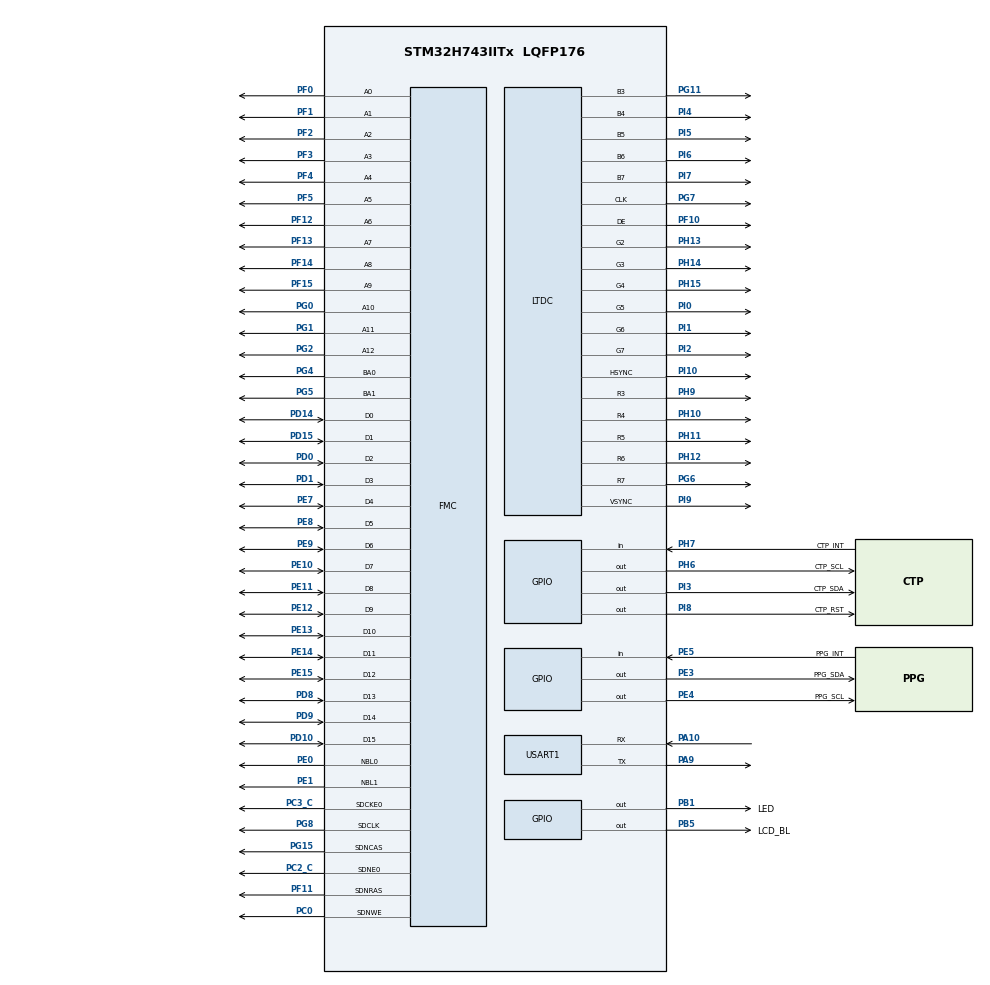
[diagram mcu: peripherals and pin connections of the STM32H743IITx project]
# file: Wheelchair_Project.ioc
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CORTEX_M7.AccessPermission_S-Cortex_Memory_Protection_Unit_Region1_Settings_S=MPU_REGION_FULL_ACCESS
CORTEX_M7.AccessPermission_S-Cortex_Memory_Protection_Unit_Region2_Settings_S=MPU_REGION_FULL_ACCESS
CORTEX_M7.AccessPermission_S-Cortex_Memory_Protection_Unit_Region3_Settings_S=MPU_REGION_FULL_ACCESS
CORTEX_M7.AccessPermission_S-Cortex_Memory_Protection_Unit_Region4_Settings_S=MPU_REGION_FULL_ACCESS
CORTEX_M7.AccessPermission_S-Cortex_Memory_Protection_Unit_Region5_Settings_S=MPU_REGION_FULL_ACCESS
CORTEX_M7.AccessPermission_S-Cortex_Memory_Protection_Unit_Region6_Settings_S=MPU_REGION_FULL_ACCESS
CORTEX_M7.AccessPermission_Spec=MPU_REGION_FULL_ACCESS
CORTEX_M7.BaseAddress_S-Cortex_Memory_Protection_Unit_Region1_Settings_S=0x24000000
CORTEX_M7.BaseAddress_S-Cortex_Memory_Protection_Unit_Region2_Settings_S=0x30000000
CORTEX_M7.BaseAddress_S-Cortex_Memory_Protection_Unit_Region3_Settings_S=0x38000000
CORTEX_M7.BaseAddress_S-Cortex_Memory_Protection_Unit_Region4_Settings_S=0x60000000
CORTEX_M7.BaseAddress_S-Cortex_Memory_Protection_Unit_Region5_Settings_S=0xC0000000
CORTEX_M7.BaseAddress_S-Cortex_Memory_Protection_Unit_Region6_Settings_S=0x80000000
CORTEX_M7.BaseAddress_Spec=0x20000000
CORTEX_M7.CPU_DCache=Enabled
CORTEX_M7.CPU_ICache=Enabled
CORTEX_M7.DisableExec_S-Cortex_Memory_Protection_Unit_Region6_Settings_S=MPU_INSTRUCTION_ACCESS_DISABLE
CORTEX_M7.DisableExec_Spec=MPU_INSTRUCTION_ACCESS_ENABLE
CORTEX_M7.Enable_S-Cortex_Memory_Protection_Unit_Region1_Settings_S=MPU_REGION_ENABLE
CORTEX_M7.Enable_S-Cortex_Memory_Protection_Unit_Region2_Settings_S=MPU_REGION_ENABLE
CORTEX_M7.Enable_S-Cortex_Memory_Protection_Unit_Region3_Settings_S=MPU_REGION_ENABLE
CORTEX_M7.Enable_S-Cortex_Memory_Protection_Unit_Region4_Settings_S=MPU_REGION_ENABLE
CORTEX_M7.Enable_S-Cortex_Memory_Protection_Unit_Region5_Settings_S=MPU_REGION_ENABLE
CORTEX_M7.Enable_S-Cortex_Memory_Protection_Unit_Region6_Settings_S=MPU_REGION_ENABLE
CORTEX_M7.IsBufferable_S-Cortex_Memory_Protection_Unit_Region2_Settings_S=MPU_ACCESS_BUFFERABLE
CORTEX_M7.IsBufferable_S-Cortex_Memory_Protection_Unit_Region3_Settings_S=MPU_ACCESS_BUFFERABLE
CORTEX_M7.IsBufferable_S-Cortex_Memory_Protection_Unit_Region5_Settings_S=MPU_ACCESS_BUFFERABLE
CORTEX_M7.IsBufferable_Spec=MPU_ACCESS_BUFFERABLE
CORTEX_M7.IsCacheable_S-Cortex_Memory_Protection_Unit_Region1_Settings_S=MPU_ACCESS_CACHEABLE
CORTEX_M7.IsCacheable_S-Cortex_Memory_Protection_Unit_Region2_Settings_S=MPU_ACCESS_CACHEABLE
CORTEX_M7.IsCacheable_S-Cortex_Memory_Protection_Unit_Region3_Settings_S=MPU_ACCESS_CACHEABLE
CORTEX_M7.IsCacheable_S-Cortex_Memory_Protection_Unit_Region5_Settings_S=MPU_ACCESS_CACHEABLE
CORTEX_M7.IsCacheable_Spec=MPU_ACCESS_CACHEABLE
CORTEX_M7.IsShareable_S-Cortex_Memory_Protection_Unit_Region1_Settings_S=MPU_ACCESS_SHAREABLE
CORTEX_M7.IsShareable_Spec=MPU_ACCESS_NOT_SHAREABLE
CORTEX_M7.Size_S-Cortex_Memory_Protection_Unit_Region1_Settings_S=MPU_REGION_SIZE_512KB
CORTEX_M7.Size_S-Cortex_Memory_Protection_Unit_Region2_Settings_S=MPU_REGION_SIZE_512KB
CORTEX_M7.Size_S-Cortex_Memory_Protection_Unit_Region3_Settings_S=MPU_REGION_SIZE_64KB
CORTEX_M7.Size_S-Cortex_Memory_Protection_Unit_Region4_Settings_S=MPU_REGION_SIZE_64MB
CORTEX_M7.Size_S-Cortex_Memory_Protection_Unit_Region5_Settings_S=MPU_REGION_SIZE_32MB
CORTEX_M7.Size_S-Cortex_Memory_Protection_Unit_Region6_Settings_S=MPU_REGION_SIZE_256MB
CORTEX_M7.Size_Spec=MPU_REGION_SIZE_128KB
CORTEX_M7.SubRegionDisable_Spec=0x0
CORTEX_M7.default_mode_Activation=1
DMA2D.ColorMode=DMA2D_OUTPUT_RGB888
FMC.CASLatency1=FMC_SDRAM_CAS_LATENCY_3
FMC.ColumnBitsNumber1=FMC_SDRAM_COLUMN_BITS_NUM_9
FMC.ExitSelfRefreshDelay1=8
FMC.LoadToActiveDelay1=2
FMC.RCDDelay1=2
FMC.RPDelay1=2
FMC.RPDelay2=2
FMC.ReadBurst1=FMC_SDRAM_RBURST_ENABLE
FMC.ReadBurst2=FMC_SDRAM_RBURST_ENABLE
FMC.ReadPipeDelay1=FMC_SDRAM_RPIPE_DELAY_1
FMC.ReadPipeDelay2=FMC_SDRAM_RPIPE_DELAY_1
FMC.RowCycleDelay1=6
FMC.RowCycleDelay2=6
FMC.SDClockPeriod1=FMC_SDRAM_CLOCK_PERIOD_2
FMC.SDClockPeriod2=FMC_SDRAM_CLOCK_PERIOD_2
FMC.SelfRefreshTime1=6
FMC.WriteRecoveryTime1=4
FREERTOS.Queues01=Queue_PPG_IR,16,float64_t,0,Dynamic,NULL,NULL;Queue_PPG_Red,16,float64_t,0,Dynamic,NULL,NULL
FREERTOS.Tasks01=touchGFX,0,2048,TouchGFX_Task,As weak,NULL,Dynamic,NULL,NULL;taskPPG,-1,1024,PPG_Task,Default,NULL,Dynamic,NULL,NULL;filterTask,1,1024,FilterTask,Default,NULL,Dynamic,NULL,NULL
FREERTOS.configENABLE_FPU=1
FREERTOS.configTOTAL_HEAP_SIZE=32768
FREERTOS.configUSE_APPLICATION_TASK_TAG=1
LTDC.ActiveW=800
LTDC.Alpha_L0=255
LTDC.Blue_L0=255
LTDC.FBStartAdress_L0=0xC0000000
LTDC.HBP=8
LTDC.HFP=8
LTDC.HSync=4
LTDC.ImageHeight_L0=480
LTDC.ImageWidth_L0=800
LTDC.Layers=0
LTDC.PixelFormat_L0=LTDC_PIXEL_FORMAT_RGB565
LTDC.Red=0xFF
LTDC.VBP=16
LTDC.VFP=20
LTDC.WindowX1_L0=800
LTDC.WindowY1_L0=480
Mcu.Family=STM32H7
Mcu.Name=STM32H743IITx
Mcu.Package=LQFP176
NVIC.DMA2D_IRQn=true\:9\:0\:true\:false\:true\:true\:true\:true\:true
NVIC.LTDC_IRQn=true\:9\:0\:true\:false\:true\:true\:true\:true\:true
NVIC.PriorityGroup=NVIC_PRIORITYGROUP_4
NVIC.TIM6_DAC_IRQn=true\:0\:0\:true\:false\:true\:false\:false\:true\:true
NVIC.TimeBase=TIM6_DAC_IRQn
NVIC.TimeBaseIP=TIM6
PA10.Mode=Asynchronous
PA10.Signal=USART1_RX
PA13\ (JTMS/SWDIO).Mode=Serial_Wire
PA13\ (JTMS/SWDIO).Signal=DEBUG_JTMS-SWDIO
PA14\ (JTCK/SWCLK).Mode=Serial_Wire
PA14\ (JTCK/SWCLK).Signal=DEBUG_JTCK-SWCLK
PA9.Mode=Asynchronous
PA9.Signal=USART1_TX
PB1.GPIO_Label=LED
PB1.GPIO_PuPd=GPIO_PULLDOWN
PB1.Signal=GPIO_Output
PB5.GPIO_Label=LCD_BL
PB5.GPIO_PuPd=GPIO_PULLUP
PB5.PinState=GPIO_PIN_SET
PB5.Signal=GPIO_Output
PC0.Signal=FMC_SDNWE
PC14-OSC32_IN\ (OSC32_IN).Mode=LSE-External-Oscillator
PC14-OSC32_IN\ (OSC32_IN).Signal=RCC_OSC32_IN
PC15-OSC32_OUT\ (OSC32_OUT).Mode=LSE-External-Oscillator
PC15-OSC32_OUT\ (OSC32_OUT).Signal=RCC_OSC32_OUT
PC2_C.Mode=SdramChipSelect1_1
PC2_C.Signal=FMC_SDNE0
PC3_C.Mode=SdramChipSelect1_1
PC3_C.Signal=FMC_SDCKE0
PD0.Signal=FMC_D2_DA2
PD1.Signal=FMC_D3_DA3
PD10.Signal=FMC_D15_DA15
PD14.Signal=FMC_D0_DA0
PD15.Signal=FMC_D1_DA1
PD8.Signal=FMC_D13_DA13
PD9.Signal=FMC_D14_DA14
PE0.Signal=FMC_NBL0
PE1.Signal=FMC_NBL1
PE10.Signal=FMC_D7_DA7
PE11.Signal=FMC_D8_DA8
PE12.Signal=FMC_D9_DA9
PE13.Signal=FMC_D10_DA10
PE14.Signal=FMC_D11_DA11
PE15.Signal=FMC_D12_DA12
PE3.GPIO_Label=PPG_SDA
PE3.GPIO_ModeDefaultOutputPP=GPIO_MODE_OUTPUT_OD
PE3.GPIO_PuPd=GPIO_NOPULL
PE3.GPIO_Speed=GPIO_SPEED_FREQ_VERY_HIGH
PE3.Signal=GPIO_Output
PE4.GPIO_Label=PPG_SCL
PE4.GPIO_ModeDefaultOutputPP=GPIO_MODE_OUTPUT_OD
PE4.GPIO_PuPd=GPIO_NOPULL
PE4.GPIO_Speed=GPIO_SPEED_FREQ_VERY_HIGH
PE4.Signal=GPIO_Output
PE5.GPIO_Label=PPG_INT
PE5.GPIO_PuPd=GPIO_PULLUP
PE5.Signal=GPIO_Input
PE7.Signal=FMC_D4_DA4
PE8.Signal=FMC_D5_DA5
PE9.Signal=FMC_D6_DA6
PF0.Signal=FMC_A0
PF1.Signal=FMC_A1
PF10.GPIO_Speed=GPIO_SPEED_FREQ_VERY_HIGH
PF10.Mode=RGB565
PF10.Signal=LTDC_DE
PF11.Signal=FMC_SDNRAS
PF12.Signal=FMC_A6
PF13.Signal=FMC_A7
PF14.Signal=FMC_A8
PF15.Signal=FMC_A9
PF2.Signal=FMC_A2
PF3.Signal=FMC_A3
PF4.Signal=FMC_A4
PF5.Signal=FMC_A5
PG0.Signal=FMC_A10
PG1.Signal=FMC_A11
PG11.GPIO_Speed=GPIO_SPEED_FREQ_VERY_HIGH
PG11.Mode=RGB565
PG11.Signal=LTDC_B3
PG15.Signal=FMC_SDNCAS
PG2.Signal=FMC_A12
PG4.Signal=FMC_A14_BA0
PG5.Signal=FMC_A15_BA1
PG6.GPIO_Speed=GPIO_SPEED_FREQ_VERY_HIGH
PG6.Mode=RGB565
PG6.Signal=LTDC_R7
PG7.GPIO_Speed=GPIO_SPEED_FREQ_VERY_HIGH
PG7.Mode=RGB565
PG7.Signal=LTDC_CLK
PG8.Signal=FMC_SDCLK
PH0-OSC_IN\ (PH0).Mode=HSE-External-Oscillator
PH0-OSC_IN\ (PH0).Signal=RCC_OSC_IN
PH1-OSC_OUT\ (PH1).Mode=HSE-External-Oscillator
PH1-OSC_OUT\ (PH1).Signal=RCC_OSC_OUT
PH10.GPIO_Speed=GPIO_SPEED_FREQ_VERY_HIGH
PH10.Mode=RGB565
PH10.Signal=LTDC_R4
PH11.GPIO_Speed=GPIO_SPEED_FREQ_VERY_HIGH
PH11.Mode=RGB565
PH11.Signal=LTDC_R5
PH12.GPIO_Speed=GPIO_SPEED_FREQ_VERY_HIGH
PH12.Mode=RGB565
PH12.Signal=LTDC_R6
PH13.GPIO_Speed=GPIO_SPEED_FREQ_VERY_HIGH
PH13.Mode=RGB565
PH13.Signal=LTDC_G2
PH14.GPIO_Speed=GPIO_SPEED_FREQ_VERY_HIGH
PH14.Mode=RGB565
PH14.Signal=LTDC_G3
PH15.GPIO_Speed=GPIO_SPEED_FREQ_VERY_HIGH
PH15.Mode=RGB565
PH15.Signal=LTDC_G4
PH6.GPIO_Label=CTP_SCL
PH6.GPIO_ModeDefaultOutputPP=GPIO_MODE_OUTPUT_OD
PH6.GPIO_PuPd=GPIO_NOPULL
PH6.GPIO_Speed=GPIO_SPEED_FREQ_VERY_HIGH
PH6.PinState=GPIO_PIN_SET
PH6.Signal=GPIO_Output
PH7.GPIO_Label=CTP_INT
PH7.Signal=GPIO_Input
PH9.GPIO_Speed=GPIO_SPEED_FREQ_VERY_HIGH
PH9.Mode=RGB565
PH9.Signal=LTDC_R3
PI0.GPIO_Speed=GPIO_SPEED_FREQ_VERY_HIGH
PI0.Mode=RGB565
PI0.Signal=LTDC_G5
PI1.GPIO_Speed=GPIO_SPEED_FREQ_VERY_HIGH
PI1.Mode=RGB565
PI1.Signal=LTDC_G6
PI10.GPIO_Speed=GPIO_SPEED_FREQ_VERY_HIGH
PI10.Mode=RGB565
PI10.Signal=LTDC_HSYNC
PI2.GPIO_Speed=GPIO_SPEED_FREQ_VERY_HIGH
PI2.Mode=RGB565
PI2.Signal=LTDC_G7
PI3.GPIO_Label=CTP_SDA
PI3.GPIO_ModeDefaultOutputPP=GPIO_MODE_OUTPUT_OD
PI3.GPIO_PuPd=GPIO_NOPULL
PI3.GPIO_Speed=GPIO_SPEED_FREQ_VERY_HIGH
PI3.PinState=GPIO_PIN_SET
PI3.Signal=GPIO_Output
PI4.GPIO_Speed=GPIO_SPEED_FREQ_VERY_HIGH
PI4.Mode=RGB565
PI4.Signal=LTDC_B4
PI5.GPIO_Speed=GPIO_SPEED_FREQ_VERY_HIGH
PI5.Mode=RGB565
PI5.Signal=LTDC_B5
PI6.GPIO_Speed=GPIO_SPEED_FREQ_VERY_HIGH
PI6.Mode=RGB565
PI6.Signal=LTDC_B6
PI7.GPIO_Speed=GPIO_SPEED_FREQ_VERY_HIGH
PI7.Mode=RGB565
PI7.Signal=LTDC_B7
PI8.GPIO_Label=CTP_RST
PI8.PinState=GPIO_PIN_SET
PI8.Signal=GPIO_Output
PI9.GPIO_Speed=GPIO_SPEED_FREQ_VERY_HIGH
PI9.Mode=RGB565
PI9.Signal=LTDC_VSYNC
ProjectManager.HeapSize=0x200
ProjectManager.StackSize=0x400
ProjectManager.TargetToolchain=STM32CubeIDE
RCC.ADCFreq_Value=100000000
RCC.APB1Freq_Value=120000000
RCC.APB2Freq_Value=120000000
RCC.APB3Freq_Value=120000000
RCC.APB4Freq_Value=120000000
RCC.CortexFreq_Value=480000000
RCC.D1PPRE=RCC_APB3_DIV2
RCC.D2PPRE1=RCC_APB1_DIV2
RCC.D2PPRE2=RCC_APB2_DIV2
RCC.D3PPRE=RCC_APB4_DIV2
RCC.DIVM1=5
RCC.DIVM2=25
RCC.DIVM3=5
RCC.DIVN1=192
RCC.DIVN2=200
RCC.DIVN3=40
RCC.DIVR2=1
RCC.DIVR3=8
RCC.EnbaleCSS=true
RCC.FMCCLockSelection=RCC_FMCCLKSOURCE_PLL2
RCC.HCLKFreq_Value=240000000
RCC.HPRE=RCC_HCLK_DIV2
RCC.PLLSourceVirtual=RCC_PLLSOURCE_HSE
RCC.PWR_Regulator_Voltage_Scale=PWR_REGULATOR_VOLTAGE_SCALE0
RCC.SYSCLKFreq_VALUE=480000000
RCC.SYSCLKSource=RCC_SYSCLKSOURCE_PLLCLK
RCC.USBFreq_Value=480000000
SH.FMC_A0.0=FMC_A0,13b-sda1
SH.FMC_A1.0=FMC_A1,13b-sda1
SH.FMC_A10.0=FMC_A10,13b-sda1
SH.FMC_A11.0=FMC_A11,13b-sda1
SH.FMC_A12.0=FMC_A12,13b-sda1
SH.FMC_A14_BA0.0=FMC_BA0,FourSdramBanks1
SH.FMC_A15_BA1.0=FMC_BA1,FourSdramBanks1
SH.FMC_A2.0=FMC_A2,13b-sda1
SH.FMC_A3.0=FMC_A3,13b-sda1
SH.FMC_A4.0=FMC_A4,13b-sda1
SH.FMC_A5.0=FMC_A5,13b-sda1
SH.FMC_A6.0=FMC_A6,13b-sda1
SH.FMC_A7.0=FMC_A7,13b-sda1
SH.FMC_A8.0=FMC_A8,13b-sda1
SH.FMC_A9.0=FMC_A9,13b-sda1
SH.FMC_D0_DA0.0=FMC_D0,sd-16b-d1
SH.FMC_D10_DA10.0=FMC_D10,sd-16b-d1
SH.FMC_D11_DA11.0=FMC_D11,sd-16b-d1
SH.FMC_D12_DA12.0=FMC_D12,sd-16b-d1
SH.FMC_D13_DA13.0=FMC_D13,sd-16b-d1
SH.FMC_D14_DA14.0=FMC_D14,sd-16b-d1
SH.FMC_D15_DA15.0=FMC_D15,sd-16b-d1
SH.FMC_D1_DA1.0=FMC_D1,sd-16b-d1
SH.FMC_D2_DA2.0=FMC_D2,sd-16b-d1
SH.FMC_D3_DA3.0=FMC_D3,sd-16b-d1
SH.FMC_D4_DA4.0=FMC_D4,sd-16b-d1
SH.FMC_D5_DA5.0=FMC_D5,sd-16b-d1
SH.FMC_D6_DA6.0=FMC_D6,sd-16b-d1
SH.FMC_D7_DA7.0=FMC_D7,sd-16b-d1
SH.FMC_D8_DA8.0=FMC_D8,sd-16b-d1
SH.FMC_D9_DA9.0=FMC_D9,sd-16b-d1
SH.FMC_NBL0.0=FMC_NBL0,Sd2ByteEnable1
SH.FMC_NBL1.0=FMC_NBL1,Sd2ByteEnable1
SH.FMC_SDCLK.0=FMC_SDCLK,13b-sda1
SH.FMC_SDNCAS.0=FMC_SDNCAS,13b-sda1
SH.FMC_SDNRAS.0=FMC_SDNRAS,13b-sda1
SH.FMC_SDNWE.0=FMC_SDNWE,13b-sda1
STMicroelectronics.X-CUBE-ALGOBUILD.1.4.0.LibraryCcDSPOoLibraryJjDSPOoLibrary=true
STMicroelectronics.X-CUBE-TOUCHGFX.4.23.2.ApplicationCcGraphicsJjApplication=TouchGFXOoGenerator
STMicroelectronics.X-CUBE-TOUCHGFX.4.23.2.tgfx_address1=0xC0000000
STMicroelectronics.X-CUBE-TOUCHGFX.4.23.2.tgfx_address2=0xC00BB800
STMicroelectronics.X-CUBE-TOUCHGFX.4.23.2.tgfx_buffering_strategy=Double
STMicroelectronics.X-CUBE-TOUCHGFX.4.23.2.tgfx_custom_height=480
STMicroelectronics.X-CUBE-TOUCHGFX.4.23.2.tgfx_display_interface=disp_ltdc
STMicroelectronics.X-CUBE-TOUCHGFX.4.23.2.tgfx_hardware_accelerator=dma_2d
STMicroelectronics.X-CUBE-TOUCHGFX.4.23.2.tgfx_location=By Address
STMicroelectronics.X-CUBE-TOUCHGFX.4.23.2.tgfx_pixel_format=RGB565\:16
STMicroelectronics.X-CUBE-TOUCHGFX.4.23.2.tgfx_vsync=vsync_ltdc
STMicroelectronics.X-CUBE-TOUCHGFX.4.23.2_IsPackSelfContextualization=true
USART1.VirtualMode-Asynchronous=VM_ASYNC
VP_CRC_VS_CRC.Mode=CRC_Activate
VP_DMA2D_VS_DMA2D.Mode=DMA2D_Activate
VP_FREERTOS_VS_CMSIS_V1.Mode=CMSIS_V1
VP_STMicroelectronics.X-CUBE-ALGOBUILD_VS_DSPOoLibraryJjLibrary_1.4.0_1.4.0.Mode=DSPOoLibraryJjLibrary
VP_STMicroelectronics.X-CUBE-TOUCHGFX_VS_GraphicsJjApplication_4.23.2.Mode=GraphicsJjApplication
VP_SYS_VS_tim6.Mode=TIM6
board=custom

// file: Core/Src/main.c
/* USER CODE BEGIN Header */
/**
  ******************************************************************************
  * @file           : main.c
  * @brief          : Main program body
  ******************************************************************************
  * @attention
  *
  * Copyright (c) 2024 STMicroelectronics.
  * All rights reserved.
  *
  * This software is licensed under terms that can be found in the LICENSE file
  * in the root directory of this software component.
  * If no LICENSE file comes with this software, it is provided AS-IS.
  *
  ******************************************************************************
  */
/* USER CODE END Header */
#include "main.h"
#include "cmsis_os.h"
#include "crc.h"
#include "dma2d.h"
#include "ltdc.h"
#include "usart.h"
#include "gpio.h"
#include "fmc.h"
#include "app_touchgfx.h"

void SystemClock_Config(void);
static void MPU_Config(void);
void MX_FREERTOS_Init(void);

int main(void)
{

  /* MPU Configuration--------------------------------------------------------*/
  MPU_Config();

  /* Enable the CPU Cache */

  /* Enable I-Cache---------------------------------------------------------*/
  SCB_EnableICache();

  /* Enable D-Cache---------------------------------------------------------*/
  SCB_EnableDCache();

  /* MCU Configuration--------------------------------------------------------*/

  /* Reset of all peripherals, Initializes the Flash interface and the Systick. */
  HAL_Init();

  /* USER CODE BEGIN Init */
    SCB->CACR |= 1 << 2;
  /* USER CODE END Init */

  /* Configure the system clock */
  SystemClock_Config();

  /* USER CODE BEGIN SysInit */
    delay_init();
  /* USER CODE END SysInit */

  /* Initialize all configured peripherals */
  MX_GPIO_Init();
  MX_DMA2D_Init();
  MX_LTDC_Init();
  MX_CRC_Init();
  MX_FMC_Init();
  MX_USART1_UART_Init();
  MX_TouchGFX_Init();
  /* Call PreOsInit function */
  MX_TouchGFX_PreOSInit();
  /* USER CODE BEGIN 2 */
    HAL_UART_Transmit(&huart1, "SDRAM W9825G6KH Init success\n", 30, 100);
    MAX_Init();
  /* USER CODE END 2 */

  /* Call init function for freertos objects (in cmsis_os2.c) */
  MX_FREERTOS_Init();

  /* Start scheduler */
  osKernelStart();

  /* We should never get here as control is now taken by the scheduler */

  /* Infinite loop */
  while (1)
  {

  }
}

void SystemClock_Config(void)
{
  RCC_OscInitTypeDef RCC_OscInitStruct = {0};
  RCC_ClkInitTypeDef RCC_ClkInitStruct = {0};

  /** Supply configuration update enable
  */
  HAL_PWREx_ConfigSupply(PWR_LDO_SUPPLY);

  /** Configure the main internal regulator output voltage
  */
  __HAL_PWR_VOLTAGESCALING_CONFIG(PWR_REGULATOR_VOLTAGE_SCALE1);

  while(!__HAL_PWR_GET_FLAG(PWR_FLAG_VOSRDY)) {}

  __HAL_RCC_SYSCFG_CLK_ENABLE();
  __HAL_PWR_VOLTAGESCALING_CONFIG(PWR_REGULATOR_VOLTAGE_SCALE0);

  while(!__HAL_PWR_GET_FLAG(PWR_FLAG_VOSRDY)) {}

  /** Initializes the RCC Oscillators according to the specified parameters
  * in the RCC_OscInitTypeDef structure.
  */
  RCC_OscInitStruct.OscillatorType = RCC_OSCILLATORTYPE_HSE;
  RCC_OscInitStruct.HSEState = RCC_HSE_ON;
  RCC_OscInitStruct.PLL.PLLState = RCC_PLL_ON;
  RCC_OscInitStruct.PLL.PLLSource = RCC_PLLSOURCE_HSE;
  RCC_OscInitStruct.PLL.PLLM = 5;
  RCC_OscInitStruct.PLL.PLLN = 192;
  RCC_OscInitStruct.PLL.PLLP = 2;
  RCC_OscInitStruct.PLL.PLLQ = 2;
  RCC_OscInitStruct.PLL.PLLR = 2;
  RCC_OscInitStruct.PLL.PLLRGE = RCC_PLL1VCIRANGE_2;
  RCC_OscInitStruct.PLL.PLLVCOSEL = RCC_PLL1VCOWIDE;
  RCC_OscInitStruct.PLL.PLLFRACN = 0;
  if (HAL_RCC_OscConfig(&RCC_OscInitStruct) != HAL_OK)
  {
    Error_Handler();
  }

  /** Initializes the CPU, AHB and APB buses clocks
  */
  RCC_ClkInitStruct.ClockType = RCC_CLOCKTYPE_HCLK|RCC_CLOCKTYPE_SYSCLK
                              |RCC_CLOCKTYPE_PCLK1|RCC_CLOCKTYPE_PCLK2
                              |RCC_CLOCKTYPE_D3PCLK1|RCC_CLOCKTYPE_D1PCLK1;
  RCC_ClkInitStruct.SYSCLKSource = RCC_SYSCLKSOURCE_PLLCLK;
  RCC_ClkInitStruct.SYSCLKDivider = RCC_SYSCLK_DIV1;
  RCC_ClkInitStruct.AHBCLKDivider = RCC_HCLK_DIV2;
  RCC_ClkInitStruct.APB3CLKDivider = RCC_APB3_DIV2;
  RCC_ClkInitStruct.APB1CLKDivider = RCC_APB1_DIV2;
  RCC_ClkInitStruct.APB2CLKDivider = RCC_APB2_DIV2;
  RCC_ClkInitStruct.APB4CLKDivider = RCC_APB4_DIV2;

  if (HAL_RCC_ClockConfig(&RCC_ClkInitStruct, FLASH_LATENCY_4) != HAL_OK)
  {
    Error_Handler();
  }

  /** Enables the Clock Security System
  */
  HAL_RCC_EnableCSS();
}

 /* MPU Configuration */

void MPU_Config(void)
{
  MPU_Region_InitTypeDef MPU_InitStruct = {0};

  /* Disables the MPU */
  HAL_MPU_Disable();

  /** Initializes and configures the Region and the memory to be protected
  */
  MPU_InitStruct.Enable = MPU_REGION_ENABLE;
  MPU_InitStruct.Number = MPU_REGION_NUMBER0;
  MPU_InitStruct.BaseAddress = 0x20000000;
  MPU_InitStruct.Size = MPU_REGION_SIZE_128KB;
  MPU_InitStruct.SubRegionDisable = 0x0;
  MPU_InitStruct.TypeExtField = MPU_TEX_LEVEL0;
  MPU_InitStruct.AccessPermission = MPU_REGION_FULL_ACCESS;
  MPU_InitStruct.DisableExec = MPU_INSTRUCTION_ACCESS_ENABLE;
  MPU_InitStruct.IsShareable = MPU_ACCESS_NOT_SHAREABLE;
  MPU_InitStruct.IsCacheable = MPU_ACCESS_CACHEABLE;
  MPU_InitStruct.IsBufferable = MPU_ACCESS_BUFFERABLE;

  HAL_MPU_ConfigRegion(&MPU_InitStruct);

  /** Initializes and configures the Region and the memory to be protected
  */
  MPU_InitStruct.Number = MPU_REGION_NUMBER1;
  MPU_InitStruct.BaseAddress = 0x24000000;
  MPU_InitStruct.Size = MPU_REGION_SIZE_512KB;
  MPU_InitStruct.IsShareable = MPU_ACCESS_SHAREABLE;
  MPU_InitStruct.IsBufferable = MPU_ACCESS_NOT_BUFFERABLE;

  HAL_MPU_ConfigRegion(&MPU_InitStruct);

  /** Initializes and configures the Region and the memory to be protected
  */
  MPU_InitStruct.Number = MPU_REGION_NUMBER2;
  MPU_InitStruct.BaseAddress = 0x30000000;
  MPU_InitStruct.IsShareable = MPU_ACCESS_NOT_SHAREABLE;
  MPU_InitStruct.IsBufferable = MPU_ACCESS_BUFFERABLE;

  HAL_MPU_ConfigRegion(&MPU_InitStruct);

  /** Initializes and configures the Region and the memory to be protected
  */
  MPU_InitStruct.Number = MPU_REGION_NUMBER3;
  MPU_InitStruct.BaseAddress = 0x38000000;
  MPU_InitStruct.Size = MPU_REGION_SIZE_64KB;

  HAL_MPU_ConfigRegion(&MPU_InitStruct);

  /** Initializes and configures the Region and the memory to be protected
  */
  MPU_InitStruct.Number = MPU_REGION_NUMBER4;
  MPU_InitStruct.BaseAddress = 0x60000000;
  MPU_InitStruct.Size = MPU_REGION_SIZE_64MB;
  MPU_InitStruct.IsCacheable = MPU_ACCESS_NOT_CACHEABLE;
  MPU_InitStruct.IsBufferable = MPU_ACCESS_NOT_BUFFERABLE;

  HAL_MPU_ConfigRegion(&MPU_InitStruct);

  /** Initializes and configures the Region and the memory to be protected
  */
  MPU_InitStruct.Number = MPU_REGION_NUMBER5;
  MPU_InitStruct.BaseAddress = 0xC0000000;
  MPU_InitStruct.Size = MPU_REGION_SIZE_32MB;
  MPU_InitStruct.IsCacheable = MPU_ACCESS_CACHEABLE;
  MPU_InitStruct.IsBufferable = MPU_ACCESS_BUFFERABLE;

  HAL_MPU_ConfigRegion(&MPU_InitStruct);

  /** Initializes and configures the Region and the memory to be protected
  */
  MPU_InitStruct.Number = MPU_REGION_NUMBER6;
  MPU_InitStruct.BaseAddress = 0x80000000;
  MPU_InitStruct.Size = MPU_REGION_SIZE_256MB;
  MPU_InitStruct.DisableExec = MPU_INSTRUCTION_ACCESS_DISABLE;
  MPU_InitStruct.IsCacheable = MPU_ACCESS_NOT_CACHEABLE;
  MPU_InitStruct.IsBufferable = MPU_ACCESS_NOT_BUFFERABLE;

  HAL_MPU_ConfigRegion(&MPU_InitStruct);
  /* Enables the MPU */
  HAL_MPU_Enable(MPU_PRIVILEGED_DEFAULT);

}

void HAL_TIM_PeriodElapsedCallback(TIM_HandleTypeDef *htim)
{
  if (htim->Instance == TIM6) {
    HAL_IncTick();
  }
}

void Error_Handler(void)
{
  __disable_irq();
  while (1)
  {
  }
}

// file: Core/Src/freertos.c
/* USER CODE BEGIN Header */
/**
  ******************************************************************************
  * File Name          : freertos.c
  * Description        : Code for freertos applications
  ******************************************************************************
  * @attention
  *
  * Copyright (c) 2024 STMicroelectronics.
  * All rights reserved.
  *
  * This software is licensed under terms that can be found in the LICENSE file
  * in the root directory of this software component.
  * If no LICENSE file comes with this software, it is provided AS-IS.
  *
  ******************************************************************************
  */
/* USER CODE END Header */

#include "FreeRTOS.h"
#include "task.h"
#include "main.h"
#include "cmsis_os.h"

/* USER CODE BEGIN Includes */
#include "stream_buffer.h"
#include "filtering_algorithms.h"
/* USER CODE END Includes */

/* USER CODE BEGIN Variables */
float64_t test_data[400] =
        {
                1700818, 1989363, 1994475, 1996110, 1997032, 1997350, 1997110, 1996960, 1996969, 1996949, 1997004,
                1997299, 1997674, 1998283, 2261279, 2261813, 2262108, 2262302, 2262452, 2262521,
                2262540, 2262558, 2262545, 2262545, 2262563, 2262592, 2262522, 2262249, 2262191, 2262350, 2262562,
                2262789, 2262882, 2262859, 2262836, 2262903, 2262983, 2263104, 2263136, 2263115,
                2263021, 2262968, 2262953, 2262962, 2262965, 2263011, 2263029, 2263017, 2262895, 2262748, 2262759,
                2262830, 2262864, 2262905, 2262896, 2262887, 2262864, 2262864, 2262861, 2262867,
                2262860, 2262869, 2262866, 2262872, 2262868, 2262868, 2262885, 2262829, 2262656, 2262594, 2262644,
                2262683, 2262714, 2262749, 2262731, 2262718, 2262715, 2262737, 2262755, 2262763,
                2262790, 2262798, 2262797, 2262808, 2262802, 2262746, 2262588, 2262564, 2262630, 2262680, 2262702,
                2262722, 2262719, 2262698, 2262699, 2262713, 2262712, 2262728, 2262724, 2262730,
                2262728, 2262733, 2262751, 2262632, 2262464, 2262483, 2262547, 2262599, 2262629, 2262638, 2262635,
                2262621, 2262613, 2262613, 2262630, 2262646, 2262659, 2262666, 2262675, 2262674,
                2262690, 2262688, 2262644, 2262450, 2262421, 2262497, 2262555, 2262595, 2262625, 2262618, 2262621,
                2262614, 2262605, 2262624, 2262632, 2262631, 2262605, 2262587, 2262560, 2262553,
                2262560, 2262561, 2262573, 2262441, 2262279, 2262306, 2262398, 2262467, 2262488, 2262518, 2262522,
                2262498, 2262490, 2262496, 2262526, 2262566, 2262586, 2262606, 2262639, 2262644,
                2262653, 2262662, 2262669, 2262610, 2262425, 2262349, 2262389, 2262425, 2262451, 2262458, 2262455,
                2262435, 2262449, 2262457, 2262501, 2262510, 2262493, 2262488, 2262472, 2262478,
                2262501, 2262508, 2262445, 2262307, 2262293, 2262357, 2262404, 2262418, 2262426, 2262429, 2262401,
                2262403, 2262405, 2262432, 2262438, 2262448, 2262454, 2262460, 2262448, 2262386,
                2262224, 2262209, 2262275, 2262324, 2262363, 2262382, 2262388, 2262372, 2262371, 2262378, 2262379,
                2262402, 2262402, 2262414, 2262416, 2262405, 2262221, 2262109, 2262157, 2262210,
                2262264, 2262288, 2262300, 2262293, 2262292, 2262286, 2262303, 2262317, 2262336, 2262338, 2262336,
                2262344, 2262318, 2262133, 2262024, 2262100, 2262151, 2262195, 2262224, 2262229,
                2262213, 2262208, 2262214, 2262223, 2262242, 2262249, 2262259, 2262271, 2262265, 2262263, 2262272,
                2262155, 2261985, 2262003, 2262069, 2262109, 2262125, 2262157, 2262145, 2262140,
                2262135, 2262137, 2262165, 2262179, 2262183, 2262200, 2262224, 2262212, 2262204, 2262213, 2262226,
                2262197, 2262047, 2261985, 2262045, 2262092, 2262109, 2262133, 2262117, 2262112,
                2262103, 2262125, 2262131, 2262145, 2262152, 2262160, 2262166, 2262167, 2262166, 2262170, 2262171,
                2262191, 2262186, 2262120, 2261943, 2261919, 2261986, 2262041, 2262068, 2262084,
                2262086, 2262065, 2262066, 2262073, 2262092, 2262107, 2262106, 2262114, 2262132, 2262123, 2262114,
                2262133, 2262134, 2262139, 2262140, 2262065, 2261904, 2261894, 2261982, 2262014,
                2262044, 2262066, 2262059, 2262039, 2262038, 2262048, 2262059, 2262084, 2262079, 2262091, 2262100,
                2262109, 2262105, 2262116, 2262127, 2262120, 2262083, 2261935, 2261846, 2261902,
                2261972, 2262012, 2262024, 2262019, 2262005, 2262005, 2262006, 2262024, 2262030, 2262046, 2262056,
                2262066, 2262055, 2262056, 2262059, 2262060, 2262077, 2262078, 2261970, 2261832,
                2261861, 2261926, 2261972, 2261989, 2262012, 2261980, 2261973, 2261986, 2261990, 2262008, 2262018,
                2262025, 2262024, 2262024, 2262029, 2262021, 2262036, 2262039, 2262050, 2262037,
                2261900, 2261795, 2261850, 2261906, 2261935, 2261958, 2261950, 2261958, 2261944, 2261947, 2261963,
                2261977, 2261984, 2262003, 2261995, 2262006, 2262005, 2262001, 2262008, 2262018,
        };

StructBuffer Red_Data_Buffer;
StructBuffer Red_AC_Buffer;
/* USER CODE END Variables */
osThreadId touchGFXHandle;
osThreadId taskPPGHandle;
osThreadId filterTaskHandle;
osMessageQId Queue_PPG_IRHandle;
osMessageQId Queue_PPG_RedHandle;

void TouchGFX_Task(void const * argument);
void PPG_Task(void const * argument);
void FilterTask(void const * argument);

void MX_FREERTOS_Init(void); /* (MISRA C 2004 rule 8.1) */

/* GetIdleTaskMemory prototype (linked to static allocation support) */
void vApplicationGetIdleTaskMemory( StaticTask_t **ppxIdleTaskTCBBuffer, StackType_t **ppxIdleTaskStackBuffer, uint32_t *pulIdleTaskStackSize );

/* USER CODE BEGIN GET_IDLE_TASK_MEMORY */
static StaticTask_t xIdleTaskTCBBuffer;
static StackType_t xIdleStack[configMINIMAL_STACK_SIZE];

void vApplicationGetIdleTaskMemory(StaticTask_t **ppxIdleTaskTCBBuffer, StackType_t **ppxIdleTaskStackBuffer,
                                   uint32_t *pulIdleTaskStackSize) {
    *ppxIdleTaskTCBBuffer = &xIdleTaskTCBBuffer;
    *ppxIdleTaskStackBuffer = &xIdleStack[0];
    *pulIdleTaskStackSize = configMINIMAL_STACK_SIZE;
    /* place for user code */
}
/* USER CODE END GET_IDLE_TASK_MEMORY */

void MX_FREERTOS_Init(void) {

  /* Create the queue(s) */
  /* definition and creation of Queue_PPG_IR */
  osMessageQDef(Queue_PPG_IR, 16, float64_t);
  Queue_PPG_IRHandle = osMessageCreate(osMessageQ(Queue_PPG_IR), NULL);

  /* definition and creation of Queue_PPG_Red */
  osMessageQDef(Queue_PPG_Red, 16, float64_t);
  Queue_PPG_RedHandle = osMessageCreate(osMessageQ(Queue_PPG_Red), NULL);

  /* Create the thread(s) */
  /* definition and creation of touchGFX */
  osThreadDef(touchGFX, TouchGFX_Task, osPriorityNormal, 0, 2048);
  touchGFXHandle = osThreadCreate(osThread(touchGFX), NULL);

  /* definition and creation of taskPPG */
  osThreadDef(taskPPG, PPG_Task, osPriorityBelowNormal, 0, 1024);
  taskPPGHandle = osThreadCreate(osThread(taskPPG), NULL);

  /* definition and creation of filterTask */
  osThreadDef(filterTask, FilterTask, osPriorityAboveNormal, 0, 1024);
  filterTaskHandle = osThreadCreate(osThread(filterTask), NULL);

}

__weak void TouchGFX_Task(void const * argument)
{
    for (;;) {
        osDelay(1);
    }
}

void PPG_Task(void const * argument)
{
  /* USER CODE BEGIN PPG_Task */
    int a = 0;
    /* Infinite loop */
    for (;;) {
        uint32_t IR_data_raw = 0, RED_data_raw = 0;
        float64_t IR_data = 0, RED_data = 0;
        if (HAL_GPIO_ReadPin(PPG_INT_GPIO_Port, PPG_INT_Pin) == GPIO_PIN_RESET) {
            // MAX_Read_N_Samples(17, MAX_IR_Sample_Buffer, MAX_RED_Sample_Buffer);
            MAX_Read_One_Sample(&IR_data_raw, &RED_data_raw);
            IR_data = test_data[a];
            RED_data = test_data[a];
            a = (a + 1) % 400;
            if(a == 399) HAL_UART_Transmit(&huart1, (uint8_t *)"Cycle\n", 6, 1000);
//            IR_data = (float32_t) IR_data_raw;
//            RED_data = (float32_t) RED_data_raw;
            if (IR_data > 100000)
                if (xQueueSend(Queue_PPG_IRHandle, &IR_data, portMAX_DELAY) == errQUEUE_FULL)
                    HAL_UART_Transmit(&huart1, (uint8_t *) "Queue IR Full\n", 15, 1000);
            if (RED_data > 100000)
                if (xQueueSend(Queue_PPG_RedHandle, &RED_data, portMAX_DELAY) == errQUEUE_FULL)
                    HAL_UART_Transmit(&huart1, (uint8_t *) "Queue Red Full\n", 16, 1000);
        }

        osDelay(20);
    }
  /* USER CODE END PPG_Task */
}

void FilterTask(void const * argument)
{
  /* USER CODE BEGIN FilterTask */
//    StructWindowAVG * Red_Avg = slide_avg_init(50, &Red_Data_Buffer);
    StructWindowMinMax * Red_MinMax = slide_minmax_init();
    float64_t max_red_ac = 0, min_red_ac = 0;
    float64_t avg_red = 0, red_ac = 0, minmaxed_red = 0;
    /* Infinite loop */
    for (;;) {
        char str[40] = "";
        float64_t IR_data = 0, Red_data = 0;
        if (xQueueReceive(Queue_PPG_RedHandle, &Red_data, portMAX_DELAY) == pdFALSE);
        if (xQueueReceive(Queue_PPG_IRHandle, &IR_data, portMAX_DELAY) == pdFALSE);
        avg_red = update_window_avg(&Red_Data_Buffer, Red_data);
        red_ac = Red_data - avg_red;
        update_window_avg(&Red_AC_Buffer, red_ac);
        update_window_MinMax(Red_MinMax, red_ac, Red_AC_Buffer.RemovedValue, &max_red_ac, &min_red_ac);
        minmaxed_red = red_ac / (max_red_ac - min_red_ac);
        sprintf(str, "PPG: %lf,%lf,%lf,%lf\n", IR_data, minmaxed_red, max_red_ac, min_red_ac);
        HAL_UART_Transmit(&huart1, str, strlen(str), 1000);
        osDelay(pdMS_TO_TICKS(10));
    }
  /* USER CODE END FilterTask */
}
